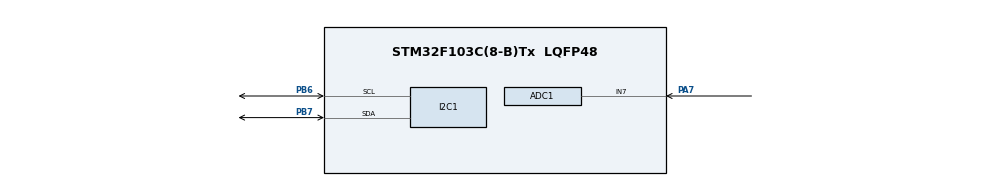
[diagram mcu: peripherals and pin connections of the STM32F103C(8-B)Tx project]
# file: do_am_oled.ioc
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ADC1.Channel-5\#ChannelRegularConversion=ADC_CHANNEL_7
ADC1.NbrOfConversionFlag=1
ADC1.Rank-5\#ChannelRegularConversion=1
ADC1.SamplingTime-5\#ChannelRegularConversion=ADC_SAMPLETIME_1CYCLE_5
ADC1.master=1
Mcu.Family=STM32F1
Mcu.Name=STM32F103C(8-B)Tx
Mcu.Package=LQFP48
NVIC.PriorityGroup=NVIC_PRIORITYGROUP_4
PA13.Mode=Serial_Wire
PA13.Signal=SYS_JTMS-SWDIO
PA14.Mode=Serial_Wire
PA14.Signal=SYS_JTCK-SWCLK
PA7.Signal=SharedAnalog_PA7
PB6.Mode=I2C
PB6.Signal=I2C1_SCL
PB7.Mode=I2C
PB7.Signal=I2C1_SDA
ProjectManager.HeapSize=0x200
ProjectManager.StackSize=0x400
ProjectManager.TargetToolchain=STM32CubeIDE
RCC.APB1Freq_Value=8000000
RCC.APB2Freq_Value=8000000
SH.SharedAnalog_PA7.0=GPIO_Analog
SH.SharedAnalog_PA7.1=ADC1_IN7,IN7
board=custom

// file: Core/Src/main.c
/* USER CODE BEGIN Header */
/**
  ******************************************************************************
  * @file           : main.c
  * @brief          : Main program body
  ******************************************************************************
  * @attention
  *
  * Copyright (c) 2025 STMicroelectronics.
  * All rights reserved.
  *
  * This software is licensed under terms that can be found in the LICENSE file
  * in the root directory of this software component.
  * If no LICENSE file comes with this software, it is provided AS-IS.
  *
  ******************************************************************************
  */
/* USER CODE END Header */
#include "main.h"
#include "oled_ssd1306.h"
#include "font5x7.h"
#include <stdio.h>

#define adc_kho 4095.0f
#define adc_uot 1300.0f
#define vref 3.3f

uint32_t read_adc_avg(ADC_HandleTypeDef *hadc, int s){
	uint32_t sum=0;
	for (int i = 0; i < s; i++) {
		HAL_ADC_Start(hadc);
		HAL_ADC_PollForConversion(hadc, 10);
		sum += HAL_ADC_GetValue(hadc);
		HAL_ADC_Stop(hadc);
		HAL_Delay(5);

	}
	return sum / s;
}

float adc_to_volt(uint32_t raw){
	return (float)raw * vref / 4095.0f;

}

float adc_to_percent(uint32_t raw){
	float doam = (adc_kho - (float)raw) / (adc_kho - adc_uot) *100.0f;
	if (doam < 0.0f) {
		doam = 0.0f;
	}
	if (doam > 100.0f) {
		doam = 100.0f;
	}
	return doam;

}

ADC_HandleTypeDef hadc1;

I2C_HandleTypeDef hi2c1;

void SystemClock_Config(void);
static void MX_GPIO_Init(void);
static void MX_I2C1_Init(void);
static void MX_ADC1_Init(void);

int main(void)
{

  /* MCU Configuration--------------------------------------------------------*/

  /* Reset of all peripherals, Initializes the Flash interface and the Systick. */
  HAL_Init();

  /* Configure the system clock */
  SystemClock_Config();

  /* Initialize all configured peripherals */
  MX_GPIO_Init();
  MX_I2C1_Init();
  MX_ADC1_Init();
  /* USER CODE BEGIN 2 */
  ssd1306_init();
  //ssd1306_clear();
  //ssd1306_writeString("hello chay duoc chua", 0, 0, Font_5x7);
  //ssd1306_updateScreen();
  /* USER CODE END 2 */
  char buf[16];
  /* Infinite loop */
  while (1)
  {
	 HAL_ADC_Start(&hadc1);
	 HAL_ADC_PollForConversion(&hadc1, HAL_MAX_DELAY);
	 uint32_t raw = read_adc_avg(&hadc1, 8);
	 //float volt = adc_to_volt(raw);
	 float doam = adc_to_percent(raw);
	 sprintf(buf, "DO AM = %.2f", doam);
	 ssd1306_clear();
	 ssd1306_writeString(buf, 20, 5, Font_5x7);
	 	  //ssd1306_updateScreen();
	 if(doam > 60.0f){
		 ssd1306_writeString("KHONG CAN TUOI NUOC!!!!", 15, 15, Font_5x7);
	 		 // ssd1306_updateScreen();
	 }else if (doam < 50.0f) {
		 ssd1306_writeString("DAT KHO!!!", 15, 15, Font_5x7);
		 ssd1306_writeString("CAN TUOI NUOC!!!", 15, 25, Font_5x7);
			//ssd1306_updateScreen();
		}
	 ssd1306_updateScreen();
	 HAL_Delay(200);
  }
}

void SystemClock_Config(void)
{
  RCC_OscInitTypeDef RCC_OscInitStruct = {0};
  RCC_ClkInitTypeDef RCC_ClkInitStruct = {0};
  RCC_PeriphCLKInitTypeDef PeriphClkInit = {0};

  /** Initializes the RCC Oscillators according to the specified parameters
  * in the RCC_OscInitTypeDef structure.
  */
  RCC_OscInitStruct.OscillatorType = RCC_OSCILLATORTYPE_HSI;
  RCC_OscInitStruct.HSIState = RCC_HSI_ON;
  RCC_OscInitStruct.HSICalibrationValue = RCC_HSICALIBRATION_DEFAULT;
  RCC_OscInitStruct.PLL.PLLState = RCC_PLL_NONE;
  if (HAL_RCC_OscConfig(&RCC_OscInitStruct) != HAL_OK)
  {
    Error_Handler();
  }

  /** Initializes the CPU, AHB and APB buses clocks
  */
  RCC_ClkInitStruct.ClockType = RCC_CLOCKTYPE_HCLK|RCC_CLOCKTYPE_SYSCLK
                              |RCC_CLOCKTYPE_PCLK1|RCC_CLOCKTYPE_PCLK2;
  RCC_ClkInitStruct.SYSCLKSource = RCC_SYSCLKSOURCE_HSI;
  RCC_ClkInitStruct.AHBCLKDivider = RCC_SYSCLK_DIV1;
  RCC_ClkInitStruct.APB1CLKDivider = RCC_HCLK_DIV1;
  RCC_ClkInitStruct.APB2CLKDivider = RCC_HCLK_DIV1;

  if (HAL_RCC_ClockConfig(&RCC_ClkInitStruct, FLASH_LATENCY_0) != HAL_OK)
  {
    Error_Handler();
  }
  PeriphClkInit.PeriphClockSelection = RCC_PERIPHCLK_ADC;
  PeriphClkInit.AdcClockSelection = RCC_ADCPCLK2_DIV2;
  if (HAL_RCCEx_PeriphCLKConfig(&PeriphClkInit) != HAL_OK)
  {
    Error_Handler();
  }
}

static void MX_ADC1_Init(void)
{

  ADC_ChannelConfTypeDef sConfig = {0};

  /** Common config
  */
  hadc1.Instance = ADC1;
  hadc1.Init.ScanConvMode = ADC_SCAN_DISABLE;
  hadc1.Init.ContinuousConvMode = DISABLE;
  hadc1.Init.DiscontinuousConvMode = DISABLE;
  hadc1.Init.ExternalTrigConv = ADC_SOFTWARE_START;
  hadc1.Init.DataAlign = ADC_DATAALIGN_RIGHT;
  hadc1.Init.NbrOfConversion = 1;
  if (HAL_ADC_Init(&hadc1) != HAL_OK)
  {
    Error_Handler();
  }

  /** Configure Regular Channel
  */
  sConfig.Channel = ADC_CHANNEL_7;
  sConfig.Rank = ADC_REGULAR_RANK_1;
  sConfig.SamplingTime = ADC_SAMPLETIME_1CYCLE_5;
  if (HAL_ADC_ConfigChannel(&hadc1, &sConfig) != HAL_OK)
  {
    Error_Handler();
  }

}

static void MX_I2C1_Init(void)
{

  hi2c1.Instance = I2C1;
  hi2c1.Init.ClockSpeed = 100000;
  hi2c1.Init.DutyCycle = I2C_DUTYCYCLE_2;
  hi2c1.Init.OwnAddress1 = 0;
  hi2c1.Init.AddressingMode = I2C_ADDRESSINGMODE_7BIT;
  hi2c1.Init.DualAddressMode = I2C_DUALADDRESS_DISABLE;
  hi2c1.Init.OwnAddress2 = 0;
  hi2c1.Init.GeneralCallMode = I2C_GENERALCALL_DISABLE;
  hi2c1.Init.NoStretchMode = I2C_NOSTRETCH_DISABLE;
  if (HAL_I2C_Init(&hi2c1) != HAL_OK)
  {
    Error_Handler();
  }

}

static void MX_GPIO_Init(void)
{

  /* GPIO Ports Clock Enable */
  __HAL_RCC_GPIOA_CLK_ENABLE();
  __HAL_RCC_GPIOB_CLK_ENABLE();

}

void Error_Handler(void)
{
  __disable_irq();
  while (1)
  {
  }
}
